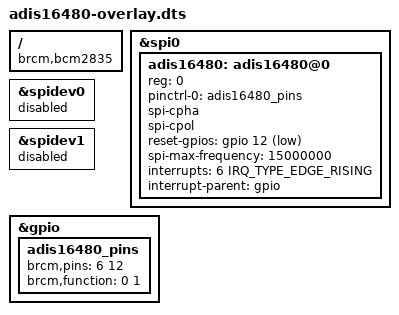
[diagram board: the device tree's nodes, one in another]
// SPDX-License-Identifier: GPL-2.0
/dts-v1/;
/plugin/;

#include <dt-bindings/interrupt-controller/irq.h>
#include <dt-bindings/gpio/gpio.h>

/ {
	compatible = "brcm,bcm2835";

	__overrides__ {
		device = <&adis16480>,"compatible";
		drdy_dio2 = <&adis16480_pins>,"brcm,pins:0=25",
				<&adis16480>,"interrupts:0=25",
				<&adis16480>,"interrupt-names=DIO2";
		drdy_dio3 = <&adis16480_pins>,"brcm,pins:0=4",
				<&adis16480>,"interrupts:0=4",
				<&adis16480>,"interrupt-names=DIO3";
		drdy_dio4 = <&adis16480_pins>,"brcm,pins:0=5",
				<&adis16480>,"interrupts:0=5",
				<&adis16480>,"interrupt-names=DIO4";
	};
};

&spi0 {
	status = "okay";
};

&spidev0 {
	status = "disabled";
};

&spidev1 {
	status = "disabled";
};

&gpio {
	adis16480_pins: adis16480_pins {
		brcm,pins = <6 12>; // interrupt and reset
		brcm,function = <0 1>; // in out
	};
};

&spi0 {
	/* needed to avoid dtc warning */
	#address-cells = <1>;
	#size-cells = <0>;

	adis16480: adis16480@0 {
		reg = <0>;
		pinctrl-names = "default";
		pinctrl-0 = <&adis16480_pins>;
		spi-cpha;
		spi-cpol;
		reset-gpios = <&gpio 12 GPIO_ACTIVE_LOW>;
		spi-max-frequency = <15000000>;
		/* use DIO1 as data ready by default */
		interrupts = <6 IRQ_TYPE_EDGE_RISING>;
		interrupt-parent = <&gpio>;
	};
};
